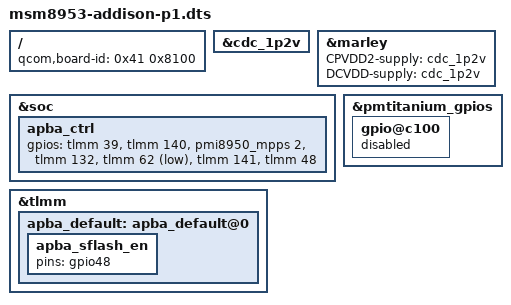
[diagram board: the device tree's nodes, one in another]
/* Copyright (c) 2015, Motorola Mobility Inc. All rights reserved.
 *
 * This program is free software; you can redistribute it and/or modify
 * it under the terms of the GNU General Public License version 2 and
 * only version 2 as published by the Free Software Foundation.
 *
 * This program is distributed in the hope that it will be useful,
 * but WITHOUT ANY WARRANTY; without even the implied warranty of
 * MERCHANTABILITY or FITNESS FOR A PARTICULAR PURPOSE.  See the
 * GNU General Public License for more details.
 */

/dts-v1/;


#include "msm8953-addison.dtsi"


/ {
	qcom,board-id = <0x41 0x8100>;
};

&cdc_1p2v {
	status = "ok";
};

&marley {
	CPVDD2-supply = <&cdc_1p2v>;
	DCVDD-supply = <&cdc_1p2v>;
};

&soc {
	apba_ctrl {
		gpios = <&tlmm 39 2>,      /* APBA_1P1_EN, output-high */
			<&tlmm 140 0>,     /* APBA_BOOTRET, output-low */
			<&pmi8950_mpps 2 2>, /* MOD_MPHY_I2S_SEL, output-high */
			<&tlmm 132 0>,     /* APBA_RESET_N, output-low */
			<&tlmm 62 1>,      /* APBA_INT_N, in */
			<&tlmm 141 2>,     /* APBA_WAKE, output-high */
			<&tlmm 48 2>;      /* APBA_SFLASH_EN, output-high */
	};
};

&tlmm {
	apba_default: apba_default@0 {
		apba_sflash_en {
			pins = "gpio48";
		};
	};
};

&pmtitanium_gpios {
	gpio@c100 {
		status = "disabled";
	};
};
